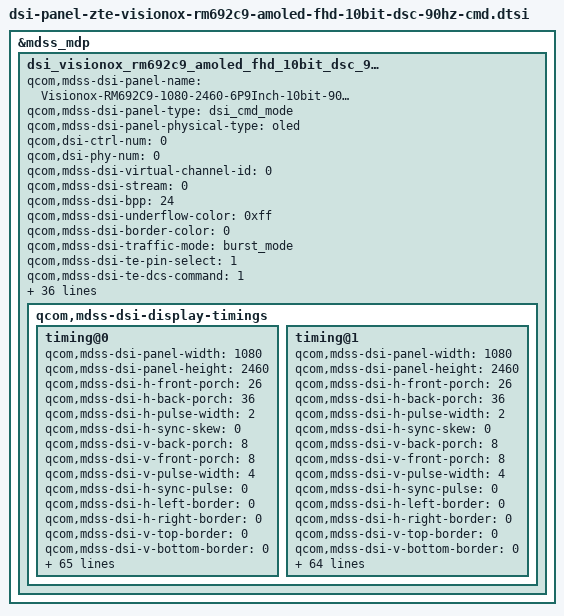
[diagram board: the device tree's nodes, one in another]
&mdss_mdp {
	dsi_visionox_rm692c9_amoled_fhd_10bit_dsc_90hz_cmd: qcom,dsi_visionox_rm692c9_10bit_dsc_90hz_cmd_display {
		qcom,mdss-dsi-panel-name = "Visionox-RM692C9-1080-2460-6P9Inch-10bit-90hz";
		qcom,mdss-dsi-panel-type = "dsi_cmd_mode";
		qcom,mdss-dsi-panel-physical-type = "oled";
		qcom,dsi-ctrl-num = <0>;
		qcom,dsi-phy-num = <0>;
		qcom,mdss-dsi-virtual-channel-id = <0>;
		qcom,mdss-dsi-stream = <0>;
		qcom,mdss-dsi-bpp = <24>;
		qcom,mdss-dsi-underflow-color = <0xff>;
		qcom,mdss-dsi-border-color = <0>;
		qcom,mdss-dsi-traffic-mode = "burst_mode";
		qcom,mdss-dsi-te-pin-select = <1>;
		qcom,mdss-dsi-te-dcs-command = <1>;
		qcom,mdss-dsi-te-check-enable;
		qcom,mdss-dsi-te-using-te-pin;
		qcom,mdss-dsi-bllp-eof-power-mode;
		qcom,mdss-dsi-bllp-power-mode;
		qcom,mdss-dsi-lane-0-state;
		qcom,mdss-dsi-lane-1-state;
		qcom,mdss-dsi-lane-2-state;
		qcom,mdss-dsi-lane-3-state;
		qcom,mdss-dsi-lp11-init;
		qcom,mdss-dsi-reset-sequence = <1 10>, <0 10>, <1 20>;
		qcom,mdss-dsi-tx-eot-append;
		qcom,mdss-dsi-post-init-delay = <1>;
		qcom,mdss-dsi-dma-trigger = "trigger_sw";
		qcom,mdss-dsi-mdp-trigger = "none";
		qcom,mdss-dsi-bl-min-level = <1>;
		qcom,mdss-dsi-bl-max-level = <2047>;
		qcom,mdss-dsi-bl-pmic-control-type = "bl_ctrl_dcs";
		qcom,mdss-dsi-panel-hdr-enabled;
		qcom,mdss-dsi-panel-hdr-color-primaries = <14630 15656 33555
			16453 11915 35880 6700 2145>;
		qcom,mdss-dsi-panel-peak-brightness = <6280000>;
		qcom,mdss-dsi-panel-blackness-level = <32>;
		qcom,mdss-pan-physical-width-dimension = <71>;
		qcom,mdss-pan-physical-height-dimension = <161>;
		zte,lcm_backlight_curve_mode = "lcd_brightness_max_rm692c9_lux";
		qcom,panel-supply-entries = <&dsi_panel_pwr_supply>;
		qcom,mdss-brightness-max-level = <255>;
		qcom,platform-te-gpio = <&tlmm 10 0>;
		qcom,platform-reset-gpio = <&pm8150l_gpios 3 0>;
		zte,lcd_dimreg_value = <40>;
		qcom,ulps-enabled;
		qcom,dsi-select-clocks = "mux_byte_clk0", "mux_pixel_clk0";
		qcom,mdss-dsi-display-timings {
			timing@0 {
				qcom,mdss-dsi-panel-width = <1080>;
				qcom,mdss-dsi-panel-height = <2460>;
				qcom,mdss-dsi-h-front-porch = <26>;
				qcom,mdss-dsi-h-back-porch = <36>;
				qcom,mdss-dsi-h-pulse-width = <2>;
				qcom,mdss-dsi-h-sync-skew = <0>;
				qcom,mdss-dsi-v-back-porch = <8>;
				qcom,mdss-dsi-v-front-porch = <8>;
				qcom,mdss-dsi-v-pulse-width = <4>;
				qcom,mdss-dsi-h-sync-pulse = <0>;
				qcom,mdss-dsi-h-left-border = <0>;
				qcom,mdss-dsi-h-right-border = <0>;
				qcom,mdss-dsi-v-top-border = <0>;
				qcom,mdss-dsi-v-bottom-border = <0>;
				qcom,mdss-dsi-panel-framerate = <60>;
				qcom,mdss-dsi-timing-switch-command = [
					39 01 00 00 00 00 02 fe d0
					39 01 00 00 00 00 02 70 81
					39 01 00 00 00 00 02 fe 00
				];
				qcom,mdss-dsi-timing-switch-command-state = "dsi_lp_mode";
				qcom,mdss-dsi-on-command = [
					39 01 00 00 00 00 02 fe 00
					39 01 00 00 00 00 02 b0 03
					39 01 00 00 00 00 02 83 43
					39 01 00 00 00 00 02 b0 04
					39 01 00 00 00 00 02 83 04
					39 01 00 00 00 00 02 b0 05
					39 01 00 00 00 00 02 83 02
					39 01 00 00 00 00 02 b0 06
					39 01 00 00 00 00 02 83 07
					39 01 00 00 00 00 02 b0 07
					39 01 00 00 00 00 02 83 08
					39 01 00 00 00 00 02 b0 08
					39 01 00 00 00 00 02 83 03
					39 01 00 00 00 00 02 b0 09
					39 01 00 00 00 00 02 83 05
					39 01 00 00 00 00 02 b0 0a
					39 01 00 00 00 00 02 83 00
					39 01 00 00 00 00 02 fe 40
					39 01 00 00 00 00 02 be 17
					39 01 00 00 00 00 02 bf bb
					39 01 00 00 00 00 02 c0 dd
					39 01 00 00 00 00 02 c1 ff
					39 01 00 00 00 00 02 fe 00
					39 01 00 00 00 00 02 fa 01
					39 01 00 00 00 00 02 fe 40
					39 01 00 00 00 00 02 82 34
					39 01 00 00 00 00 02 fe d0
					39 01 00 00 00 00 02 42 81
					39 01 00 00 00 00 02 49 01
					39 01 00 00 00 00 02 fe d2
					39 01 00 00 00 00 02 53 08
					39 01 00 00 00 00 02 72 07
					39 01 00 00 00 00 02 fe d2
					39 01 00 00 00 00 02 00 11
					39 01 00 00 00 00 02 01 ab
					39 01 00 00 00 00 02 02 30
					39 01 00 00 00 00 02 03 09
					39 01 00 00 00 00 02 04 9c
					39 01 00 00 00 00 02 05 04
					39 01 00 00 00 00 02 06 38
					39 01 00 00 00 00 02 07 02
					39 01 00 00 00 00 02 08 67
					39 01 00 00 00 00 02 09 04
					39 01 00 00 00 00 02 0a 38
					39 01 00 00 00 00 02 0b 02
					39 01 00 00 00 00 02 0c 00
					39 01 00 00 00 00 02 0d 20
					39 01 00 00 00 00 02 0e 4e
					39 01 00 00 00 00 02 0f a8
					39 01 00 00 00 00 02 10 00
					39 01 00 00 00 00 02 11 0f
					39 01 00 00 00 00 02 12 0c
					39 01 00 00 00 00 02 13 00
					39 01 00 00 00 00 02 14 29
					39 01 00 00 00 00 02 15 00
					39 01 00 00 00 00 02 16 16
					39 01 00 00 00 00 02 17 18
					39 01 00 00 00 00 02 18 00
					39 01 00 00 00 00 02 19 10
					39 01 00 00 00 00 02 1a f0
					39 01 00 00 00 00 02 1b 07
					39 01 00 00 00 00 02 1c 10
					39 01 00 00 00 00 02 1d 20
					39 01 00 00 00 00 02 1e 00
					39 01 00 00 00 00 02 1f 06
					39 01 00 00 00 00 02 20 0f
					39 01 00 00 00 00 02 21 0f
					39 01 00 00 00 00 02 22 33
					39 01 00 00 00 00 02 23 0e
					39 01 00 00 00 00 02 24 1c
					39 01 00 00 00 00 02 25 2a
					39 01 00 00 00 00 02 26 38
					39 01 00 00 00 00 02 27 46
					39 01 00 00 00 00 02 28 54
					39 01 00 00 00 00 02 29 62
					39 01 00 00 00 00 02 2a 69
					39 01 00 00 00 00 02 2b 70
					39 01 00 00 00 00 02 2d 77
					39 01 00 00 00 00 02 2f 79
					39 01 00 00 00 00 02 30 7b
					39 01 00 00 00 00 02 31 7d
					39 01 00 00 00 00 02 32 7e
					39 01 00 00 00 00 02 33 02
					39 01 00 00 00 00 02 34 02
					39 01 00 00 00 00 02 35 22
					39 01 00 00 00 00 02 36 00
					39 01 00 00 00 00 02 37 2a
					39 01 00 00 00 00 02 38 40
					39 01 00 00 00 00 02 39 2a
					39 01 00 00 00 00 02 3a be
					39 01 00 00 00 00 02 3b 3a
					39 01 00 00 00 00 02 3d fc
					39 01 00 00 00 00 02 3f 3a
					39 01 00 00 00 00 02 40 fa
					39 01 00 00 00 00 02 41 3a
					39 01 00 00 00 00 02 42 f8
					39 01 00 00 00 00 02 43 3b
					39 01 00 00 00 00 02 44 38
					39 01 00 00 00 00 02 45 3b
					39 01 00 00 00 00 02 46 78
					39 01 00 00 00 00 02 47 3b
					39 01 00 00 00 00 02 48 b6
					39 01 00 00 00 00 02 49 4b
					39 01 00 00 00 00 02 4a f6
					39 01 00 00 00 00 02 4b 4c
					39 01 00 00 00 00 02 4c 34
					39 01 00 00 00 00 02 4d 4c
					39 01 00 00 00 00 02 4e 74
					39 01 00 00 00 00 02 4f 5c
					39 01 00 00 00 00 02 50 74
					39 01 00 00 00 00 02 51 8c
					39 01 00 00 00 00 02 52 f4
					39 01 00 00 00 00 02 86 04
					39 01 00 00 00 00 02 87 38
					39 01 00 00 00 00 02 88 00
					39 01 00 00 00 00 02 89 00
					39 01 00 00 00 00 02 8a 00
					39 01 00 00 00 00 02 8b 00
					39 01 00 00 00 00 02 8c 00
					39 01 00 00 00 00 02 8d 00
					39 01 00 00 00 00 02 8e 80
					39 01 00 00 00 00 02 fe d0
					39 01 00 00 00 00 02 78 01
					39 01 00 00 00 00 02 fe 12
					39 01 00 00 00 00 02 83 20
					39 01 00 00 00 00 02 fe 00
					39 01 00 00 00 00 02 c2 08
					39 01 00 00 00 00 02 35 00
					05 01 00 00 64 00 02 11 00
					05 01 00 00 14 00 02 29 00
				];
				qcom,mdss-dsi-off-command = [
					05 01 00 00 32 00 02 28 00
					05 01 00 00 20 00 02 10 00
					39 01 00 00 00 00 02 fe 00
					39 01 00 00 00 00 02 4f 01
				];
				qcom,mdss-dsi-on-command-state = "dsi_lp_mode";
				qcom,mdss-dsi-off-command-state = "dsi_lp_mode";
				qcom,mdss-dsi-lp1-command = [
					39 01 00 00 28 00 02 fe 00
					05 01 00 00 00 00 02 39 00
				];
				qcom,mdss-dsi-lp1-command-state = "dsi_lp_mode";
				qcom,mdss-dsi-nolp-command = [
					39 01 00 00 32 00 02 fe 00
					05 01 00 00 00 00 02 38 00
				];
				qcom,mdss-dsi-nolp-command-state = "dsi_lp_mode";
				#include "dsi-panel-zte-visionox-rm692c9-common-fod.dtsi"
				zte,mdss-dsi-aod-low-commands = [
					39 01 00 00 00 00 02 fe 72
					39 01 00 00 00 00 02 69 30
					39 01 00 00 00 00 02 fe 00
				];
				zte,mdss-dsi-aod-mid-commands = [
					39 01 00 00 00 00 02 fe 72
					39 01 00 00 00 00 02 69 5c
					39 01 00 00 00 00 02 fe 00
				];
				zte,mdss-dsi-aod-high-commands = [
					39 01 00 00 00 00 02 fe 72
					39 01 00 00 00 00 02 69 b0
					39 01 00 00 00 00 02 fe 00
				];
				zte,mdss-dsi-color-original-commands = [
					39 01 00 00 00 00 02 fe 12
					39 01 00 00 00 00 02 83 00
					39 01 00 00 05 00 02 fe 00
				];
				zte,mdss-dsi-color-srgb-commands = [
					39 01 00 00 00 00 02 fe 12
					39 01 00 00 00 00 02 83 10
					39 01 00 00 05 00 02 fe 00
				];
				zte,mdss-dsi-color-p3-commands = [
					39 01 00 00 00 00 02 fe 12
					39 01 00 00 00 00 02 83 20
					39 01 00 00 05 00 02 fe 00
				];
				zte,mdss-dsi-global-hbm-on-commands = [
					39 01 00 00 00 00 02 fe 00
					39 01 00 00 00 00 02 53 e8
					39 01 00 00 05 00 02 fe 00
				];
				zte,mdss-dsi-global-hbm-off-commands = [
					39 01 00 00 00 00 02 fe 00
					39 01 00 00 00 00 02 53 28
					39 01 00 00 05 00 02 fe 00
				];
				zte,mdss-dsi-hbm-on-commands-state = "dsi_hs_mode";
				zte,mdss-dsi-hbm-off-commands-state = "dsi_hs_mode";
				zte,mdss-dsi-global-hbm-on-commands-state = "dsi_hs_mode";
				zte,mdss-dsi-global-hbm-off-commands-state = "dsi_hs_mode";
				zte,mdss-dsi-aod-low-commands-state = "dsi_hs_mode";
				zte,mdss-dsi-aod-mid-commands-state = "dsi_hs_mode";
				zte,mdss-dsi-aod-high-commands-state = "dsi_hs_mode";
				zte,mdss-dsi-color-original-commands-state = "dsi_hs_mode";
				zte,mdss-dsi-color-srgb-commands-state = "dsi_hs_mode";
				zte,mdss-dsi-color-p3-commands-state = "dsi_hs_mode";
				qcom,compression-mode = "dsc";
				qcom,mdss-dsc-slice-height = <615>;
				qcom,mdss-dsc-slice-width = <1080>;
				qcom,mdss-dsc-slice-per-pkt = <1>;
				qcom,mdss-dsc-bit-per-component = <10>;
				qcom,mdss-dsc-bit-per-pixel = <8>;
				qcom,mdss-dsc-block-prediction-enable;
				qcom,mdss-dsi-panel-phy-timings = [00 0d 03 03 06 06 04 04 02 02 04 00 0c 08];
				qcom,display-topology = <1 1 1>;
				qcom,default-topology-index = <0>;
				qcom,mdss-dsi-panel-clockrate = <380000000>;
			};

			timing@1 {
				qcom,mdss-dsi-panel-width = <1080>;
				qcom,mdss-dsi-panel-height = <2460>;
				qcom,mdss-dsi-h-front-porch = <26>;
				qcom,mdss-dsi-h-back-porch = <36>;
				qcom,mdss-dsi-h-pulse-width = <2>;
				qcom,mdss-dsi-h-sync-skew = <0>;
				qcom,mdss-dsi-v-back-porch = <8>;
				qcom,mdss-dsi-v-front-porch = <8>;
				qcom,mdss-dsi-v-pulse-width = <4>;
				qcom,mdss-dsi-h-sync-pulse = <0>;
				qcom,mdss-dsi-h-left-border = <0>;
				qcom,mdss-dsi-h-right-border = <0>;
				qcom,mdss-dsi-v-top-border = <0>;
				qcom,mdss-dsi-v-bottom-border = <0>;
				qcom,mdss-dsi-panel-framerate = <90>;
				qcom,mdss-dsi-timing-switch-command = [
					39 01 00 00 00 00 02 fe d0
					39 01 00 00 00 00 02 70 01
					39 01 00 00 00 00 02 fe 00
				];
				qcom,mdss-dsi-timing-switch-command-state = "dsi_lp_mode";
				qcom,mdss-dsi-on-command = [
					39 01 00 00 00 00 02 fe 00
					39 01 00 00 00 00 02 b0 03
					39 01 00 00 00 00 02 83 43
					39 01 00 00 00 00 02 b0 04
					39 01 00 00 00 00 02 83 04
					39 01 00 00 00 00 02 b0 05
					39 01 00 00 00 00 02 83 02
					39 01 00 00 00 00 02 b0 06
					39 01 00 00 00 00 02 83 07
					39 01 00 00 00 00 02 b0 07
					39 01 00 00 00 00 02 83 08
					39 01 00 00 00 00 02 b0 08
					39 01 00 00 00 00 02 83 03
					39 01 00 00 00 00 02 b0 09
					39 01 00 00 00 00 02 83 05
					39 01 00 00 00 00 02 b0 0a
					39 01 00 00 00 00 02 83 00
					39 01 00 00 00 00 02 fe 40
					39 01 00 00 00 00 02 be 17
					39 01 00 00 00 00 02 bf bb
					39 01 00 00 00 00 02 c0 dd
					39 01 00 00 00 00 02 c1 ff
					39 01 00 00 00 00 02 fe 00
					39 01 00 00 00 00 02 fa 01
					39 01 00 00 00 00 02 fe 40
					39 01 00 00 00 00 02 82 34
					39 01 00 00 00 00 02 fe d0
					39 01 00 00 00 00 02 42 81
					39 01 00 00 00 00 02 49 01
					39 01 00 00 00 00 02 fe d2
					39 01 00 00 00 00 02 53 08
					39 01 00 00 00 00 02 72 07
					39 01 00 00 00 00 02 fe d2
					39 01 00 00 00 00 02 00 11
					39 01 00 00 00 00 02 01 ab
					39 01 00 00 00 00 02 02 30
					39 01 00 00 00 00 02 03 09
					39 01 00 00 00 00 02 04 9c
					39 01 00 00 00 00 02 05 04
					39 01 00 00 00 00 02 06 38
					39 01 00 00 00 00 02 07 02
					39 01 00 00 00 00 02 08 67
					39 01 00 00 00 00 02 09 04
					39 01 00 00 00 00 02 0a 38
					39 01 00 00 00 00 02 0b 02
					39 01 00 00 00 00 02 0c 00
					39 01 00 00 00 00 02 0d 20
					39 01 00 00 00 00 02 0e 4e
					39 01 00 00 00 00 02 0f a8
					39 01 00 00 00 00 02 10 00
					39 01 00 00 00 00 02 11 0f
					39 01 00 00 00 00 02 12 0c
					39 01 00 00 00 00 02 13 00
					39 01 00 00 00 00 02 14 29
					39 01 00 00 00 00 02 15 00
					39 01 00 00 00 00 02 16 16
					39 01 00 00 00 00 02 17 18
					39 01 00 00 00 00 02 18 00
					39 01 00 00 00 00 02 19 10
					39 01 00 00 00 00 02 1a f0
					39 01 00 00 00 00 02 1b 07
					39 01 00 00 00 00 02 1c 10
					39 01 00 00 00 00 02 1d 20
					39 01 00 00 00 00 02 1e 00
					39 01 00 00 00 00 02 1f 06
					39 01 00 00 00 00 02 20 0f
					39 01 00 00 00 00 02 21 0f
					39 01 00 00 00 00 02 22 33
					39 01 00 00 00 00 02 23 0e
					39 01 00 00 00 00 02 24 1c
					39 01 00 00 00 00 02 25 2a
					39 01 00 00 00 00 02 26 38
					39 01 00 00 00 00 02 27 46
					39 01 00 00 00 00 02 28 54
					39 01 00 00 00 00 02 29 62
					39 01 00 00 00 00 02 2a 69
					39 01 00 00 00 00 02 2b 70
					39 01 00 00 00 00 02 2d 77
					39 01 00 00 00 00 02 2f 79
					39 01 00 00 00 00 02 30 7b
					39 01 00 00 00 00 02 31 7d
					39 01 00 00 00 00 02 32 7e
					39 01 00 00 00 00 02 33 02
					39 01 00 00 00 00 02 34 02
					39 01 00 00 00 00 02 35 22
					39 01 00 00 00 00 02 36 00
					39 01 00 00 00 00 02 37 2a
					39 01 00 00 00 00 02 38 40
					39 01 00 00 00 00 02 39 2a
					39 01 00 00 00 00 02 3a be
					39 01 00 00 00 00 02 3b 3a
					39 01 00 00 00 00 02 3d fc
					39 01 00 00 00 00 02 3f 3a
					39 01 00 00 00 00 02 40 fa
					39 01 00 00 00 00 02 41 3a
					39 01 00 00 00 00 02 42 f8
					39 01 00 00 00 00 02 43 3b
					39 01 00 00 00 00 02 44 38
					39 01 00 00 00 00 02 45 3b
					39 01 00 00 00 00 02 46 78
					39 01 00 00 00 00 02 47 3b
					39 01 00 00 00 00 02 48 b6
					39 01 00 00 00 00 02 49 4b
					39 01 00 00 00 00 02 4a f6
					39 01 00 00 00 00 02 4b 4c
					39 01 00 00 00 00 02 4c 34
					39 01 00 00 00 00 02 4d 4c
					39 01 00 00 00 00 02 4e 74
					39 01 00 00 00 00 02 4f 5c
					39 01 00 00 00 00 02 50 74
					39 01 00 00 00 00 02 51 8c
					39 01 00 00 00 00 02 52 f4
					39 01 00 00 00 00 02 86 04
					39 01 00 00 00 00 02 87 38
					39 01 00 00 00 00 02 88 00
					39 01 00 00 00 00 02 89 00
					39 01 00 00 00 00 02 8a 00
					39 01 00 00 00 00 02 8b 00
					39 01 00 00 00 00 02 8c 00
					39 01 00 00 00 00 02 8d 00
					39 01 00 00 00 00 02 8e 80
					39 01 00 00 00 00 02 fe d0
					39 01 00 00 00 00 02 70 01
					39 01 00 00 00 00 02 fe 12
					39 01 00 00 00 00 02 83 20
					39 01 00 00 00 00 02 fe 00
					39 01 00 00 00 00 02 c2 08
					39 01 00 00 00 00 02 35 00
					05 01 00 00 64 00 02 11 00
					05 01 00 00 14 00 02 29 00
				];
				qcom,mdss-dsi-off-command = [
					05 01 00 00 32 00 02 28 00
					05 01 00 00 20 00 02 10 00
					39 01 00 00 00 00 02 fe 00
					39 01 00 00 00 00 02 4f 01
				];
				qcom,mdss-dsi-on-command-state = "dsi_lp_mode";
				qcom,mdss-dsi-off-command-state = "dsi_lp_mode";
				qcom,mdss-dsi-lp1-command = [
					39 01 00 00 28 00 02 fe 00
					05 01 00 00 00 00 02 39 00
				];
				qcom,mdss-dsi-lp1-command-state = "dsi_lp_mode";
				qcom,mdss-dsi-nolp-command = [
					39 01 00 00 32 00 02 fe 00
					05 01 00 00 00 00 02 38 00
				];
				qcom,mdss-dsi-nolp-command-state = "dsi_lp_mode";
				#include "dsi-panel-zte-visionox-rm692c9-common-fod.dtsi"
				zte,mdss-dsi-aod-low-commands = [
					39 01 00 00 00 00 02 fe 72
					39 01 00 00 00 00 02 69 30
					39 01 00 00 00 00 02 fe 00
				];
				zte,mdss-dsi-aod-mid-commands = [
					39 01 00 00 00 00 02 fe 72
					39 01 00 00 00 00 02 69 5c
					39 01 00 00 00 00 02 fe 00
				];
				zte,mdss-dsi-aod-high-commands = [
					39 01 00 00 00 00 02 fe 72
					39 01 00 00 00 00 02 69 b0
					39 01 00 00 00 00 02 fe 00
				];
				zte,mdss-dsi-color-original-commands = [
					39 01 00 00 00 00 02 fe 12
					39 01 00 00 00 00 02 83 00
					39 01 00 00 05 00 02 fe 00
				];
				zte,mdss-dsi-color-srgb-commands = [
					39 01 00 00 00 00 02 fe 12
					39 01 00 00 00 00 02 83 10
					39 01 00 00 05 00 02 fe 00
				];
				zte,mdss-dsi-color-p3-commands = [
					39 01 00 00 00 00 02 fe 12
					39 01 00 00 00 00 02 83 20
					39 01 00 00 05 00 02 fe 00
				];
				zte,mdss-dsi-global-hbm-on-commands = [
					39 01 00 00 00 00 02 fe 00
					39 01 00 00 00 00 02 53 e8
					39 01 00 00 05 00 02 fe 00
				];
				zte,mdss-dsi-global-hbm-off-commands = [
					39 01 00 00 00 00 02 fe 00
					39 01 00 00 00 00 02 53 28
					39 01 00 00 05 00 02 fe 00
				];
				zte,mdss-dsi-hbm-on-commands-state = "dsi_hs_mode";
				zte,mdss-dsi-hbm-off-commands-state = "dsi_hs_mode";
				zte,mdss-dsi-global-hbm-on-commands-state = "dsi_hs_mode";
				zte,mdss-dsi-global-hbm-off-commands-state = "dsi_hs_mode";
				zte,mdss-dsi-aod-low-commands-state = "dsi_hs_mode";
				zte,mdss-dsi-aod-mid-commands-state = "dsi_hs_mode";
				zte,mdss-dsi-aod-high-commands-state = "dsi_hs_mode";
				zte,mdss-dsi-color-original-commands-state = "dsi_hs_mode";
				zte,mdss-dsi-color-srgb-commands-state = "dsi_hs_mode";
				zte,mdss-dsi-color-p3-commands-state = "dsi_hs_mode";
				qcom,compression-mode = "dsc";
				qcom,mdss-dsc-slice-height = <615>;
				qcom,mdss-dsc-slice-width = <1080>;
				qcom,mdss-dsc-slice-per-pkt = <1>;
				qcom,mdss-dsc-bit-per-component = <10>;
				qcom,mdss-dsc-bit-per-pixel = <8>;
				qcom,mdss-dsc-block-prediction-enable;
				qcom,mdss-dsi-panel-phy-timings = [00 0f 04 04 07 07 04 05 02 02 04 00 0d 08];
				qcom,display-topology = <1 1 1>;
				qcom,default-topology-index = <0>;
			};
		};
	};
};
